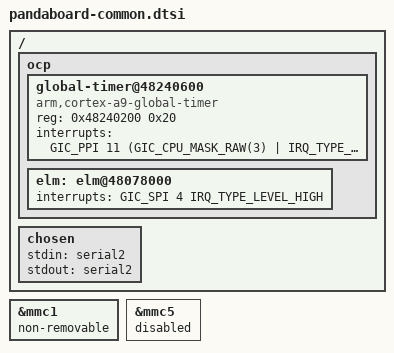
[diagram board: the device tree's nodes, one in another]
/*-
 * Copyright (c) 2015 Oleksandr Tymoshenko <gonzo@freebsd.org>
 * All rights reserved.
 *
 * Redistribution and use in source and binary forms, with or without
 * modification, are permitted provided that the following conditions
 * are met:
 * 1. Redistributions of source code must retain the above copyright
 *    notice, this list of conditions and the following disclaimer.
 * 2. Redistributions in binary form must reproduce the above copyright
 *    notice, this list of conditions and the following disclaimer in the
 *    documentation and/or other materials provided with the distribution.
 *
 * THIS SOFTWARE IS PROVIDED BY THE AUTHOR AND CONTRIBUTORS ``AS IS'' AND
 * ANY EXPRESS OR IMPLIED WARRANTIES, INCLUDING, BUT NOT LIMITED TO, THE
 * IMPLIED WARRANTIES OF MERCHANTABILITY AND FITNESS FOR A PARTICULAR PURPOSE
 * ARE DISCLAIMED. IN NO EVENT SHALL THE AUTHOR OR CONTRIBUTORS BE LIABLE
 * FOR ANY DIRECT, INDIRECT, INCIDENTAL, SPECIAL, EXEMPLARY, OR CONSEQUENTIAL
 * DAMAGES (INCLUDING, BUT NOT LIMITED TO, PROCUREMENT OF SUBSTITUTE GOODS
 * OR SERVICES; LOSS OF USE, DATA, OR PROFITS; OR BUSINESS INTERRUPTION)
 * HOWEVER CAUSED AND ON ANY THEORY OF LIABILITY, WHETHER IN CONTRACT, STRICT
 * LIABILITY, OR TORT (INCLUDING NEGLIGENCE OR OTHERWISE) ARISING IN ANY WAY
 * OUT OF THE USE OF THIS SOFTWARE, EVEN IF ADVISED OF THE POSSIBILITY OF
 * SUCH DAMAGE.
 * 
 * $FreeBSD$
 */

&mmc1 {
	non-removable; /* XXX need real solution */
};

&mmc5 {
	status = "disabled";
};

/ {
	ocp {
		global-timer@48240600 {
			compatible = "arm,cortex-a9-global-timer";
			reg = <0x48240200 0x20>;
			interrupts = <GIC_PPI 11 (GIC_CPU_MASK_RAW(3) | IRQ_TYPE_LEVEL_HIGH)>;
		};

		elm: elm@48078000 {
			interrupts = <GIC_SPI 4 IRQ_TYPE_LEVEL_HIGH>;
		};
	};
	chosen {
		stdin = "serial2";
		stdout = "serial2";
	};
};
